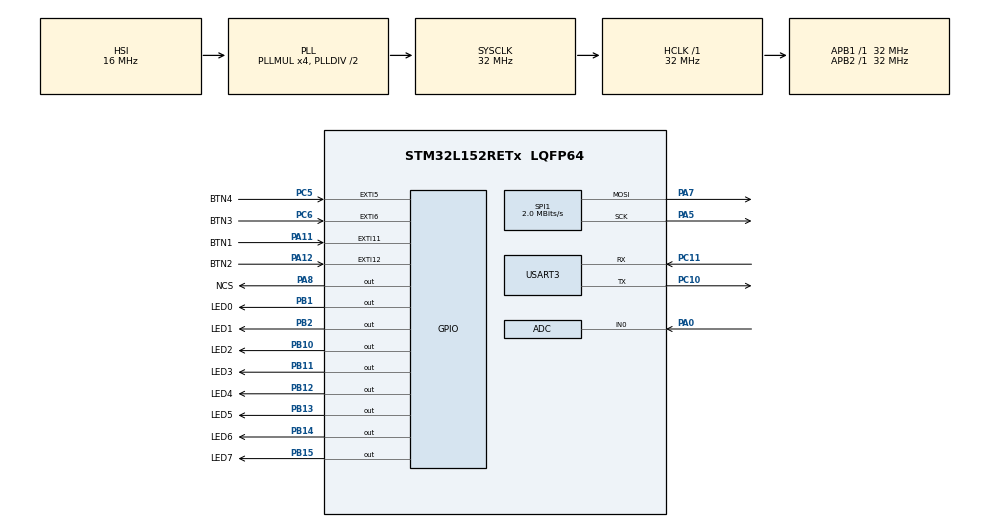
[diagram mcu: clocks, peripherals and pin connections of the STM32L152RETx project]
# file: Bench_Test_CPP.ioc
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ADC.Channel-0\#ChannelRegularConversion=ADC_CHANNEL_0
ADC.ContinuousConvMode=ENABLE
ADC.DMAContinuousRequests=DISABLE
ADC.EnableAnalogWatchDog=true
ADC.HighThreshold=4094
ADC.ITMode=ENABLE
ADC.NbrOfConversionFlag=1
ADC.Rank-0\#ChannelRegularConversion=1
ADC.SamplingTime-0\#ChannelRegularConversion=ADC_SAMPLETIME_4CYCLES
IWDG.Prescaler=IWDG_PRESCALER_4
IWDG.Reload=4095
Mcu.Family=STM32L1
Mcu.Name=STM32L152RETx
Mcu.Package=LQFP64
NVIC.ADC1_IRQn=true\:0\:0\:false\:false\:true\:true\:true\:true
NVIC.EXTI15_10_IRQn=true\:0\:0\:false\:false\:true\:true\:true\:true
NVIC.EXTI9_5_IRQn=true\:0\:0\:false\:false\:true\:true\:true\:true
NVIC.PriorityGroup=NVIC_PRIORITYGROUP_0
NVIC.TIM3_IRQn=true\:0\:0\:false\:false\:true\:true\:true\:true
NVIC.TIM6_IRQn=true\:0\:0\:false\:false\:true\:true\:true\:true
PA0-WKUP1.Mode=IN0
PA0-WKUP1.Signal=ADC_IN0
PA11.GPIO_Label=BTN1
PA11.Signal=GPXTI11
PA12.GPIO_Label=BTN2
PA12.GPIO_PuPd=GPIO_PULLDOWN
PA12.Signal=GPXTI12
PA13.Mode=Serial_Wire
PA13.Signal=SYS_JTMS-SWDIO
PA14.Mode=Serial_Wire
PA14.Signal=SYS_JTCK-SWCLK
PA5.Mode=TX_Only_Simplex_Unidirect_Master
PA5.Signal=SPI1_SCK
PA7.Mode=TX_Only_Simplex_Unidirect_Master
PA7.Signal=SPI1_MOSI
PA8.GPIO_Label=NCS
PA8.Signal=GPIO_Output
PB1.GPIO_Label=LED0
PB1.Signal=GPIO_Output
PB10.GPIO_Label=LED2
PB10.Signal=GPIO_Output
PB11.GPIO_Label=LED3
PB11.Signal=GPIO_Output
PB12.GPIO_Label=LED4
PB12.Signal=GPIO_Output
PB13.GPIO_Label=LED5
PB13.Signal=GPIO_Output
PB14.GPIO_Label=LED6
PB14.Signal=GPIO_Output
PB15.GPIO_Label=LED7
PB15.Signal=GPIO_Output
PB2.GPIO_Label=LED1
PB2.Signal=GPIO_Output
PB4.GPIO_Label=Moteur
PB4.Signal=S_TIM3_CH1
PC10.Mode=Asynchronous
PC10.Signal=USART3_TX
PC11.Mode=Asynchronous
PC11.Signal=USART3_RX
PC5.GPIO_Label=BTN4
PC5.Signal=GPXTI5
PC6.GPIO_Label=BTN3
PC6.Signal=GPXTI6
ProjectManager.HeapSize=0x200
ProjectManager.StackSize=0x400
ProjectManager.TargetToolchain=STM32CubeIDE
RCC.48MHZClocksFreq_Value=32000000
RCC.AHBFreq_Value=32000000
RCC.APB1Freq_Value=32000000
RCC.APB1TimFreq_Value=32000000
RCC.APB2Freq_Value=32000000
RCC.APB2TimFreq_Value=32000000
RCC.HCLKFreq_Value=32000000
RCC.HSE_VALUE=8000000
RCC.HSI_VALUE=16000000
RCC.LSE_VALUE=32768
RCC.MSI_VALUE=2097000
RCC.PLLMUL=RCC_PLL_MUL4
RCC.RTCClockSelectionVirtual=RCC_RTCCLKSOURCE_LSE
RCC.SYSCLKFreq_VALUE=32000000
RCC.SYSCLKSource=RCC_SYSCLKSOURCE_PLLCLK
RCC.USBOutput=48000000
RCC.VCOOutputFreq_Value=64000000
SH.S_TIM3_CH1.0=TIM3_CH1
SPI1.BaudRatePrescaler=SPI_BAUDRATEPRESCALER_16
SPI1.CalculateBaudRate=2.0 MBits/s
SPI1.Direction=SPI_DIRECTION_2LINES
SPI1.Mode=SPI_MODE_MASTER
SPI1.VirtualType=VM_MASTER
TIM3.Channel-PWM\ Generation1\ No\ Output=TIM_CHANNEL_1
TIM3.Channel-PWM\ Generation2\ No\ Output=TIM_CHANNEL_2
TIM3.Period=7
TIM3.Prescaler=32000
TIM6.Prescaler=3200
USART3.VirtualMode=VM_ASYNC
VP_IWDG_VS_IWDG.Mode=IWDG_Activate
VP_TIM3_VS_ClockSourceINT.Mode=Internal
VP_TIM3_VS_no_output1.Mode=PWM Generation1 No Output
VP_TIM3_VS_no_output2.Mode=PWM Generation2 No Output
VP_TIM6_VS_ClockSourceINT.Mode=Enable_Timer
board=NUCLEO-L152RE

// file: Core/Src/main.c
/* USER CODE BEGIN Header */
/**
 ******************************************************************************
 * @file           : main.c
 * @brief          : Main program body
 ******************************************************************************
 * @attention
 *
 * Copyright (c) 2024 STMicroelectronics.
 * All rights reserved.
 *
 * This software is licensed under terms that can be found in the LICENSE file
 * in the root directory of this software component.
 * If no LICENSE file comes with this software, it is provided AS-IS.
 *
 ******************************************************************************
 */
/* USER CODE END Header */
#include "main.h"

/* USER CODE BEGIN Includes */
#include "main.hpp"
#include "max7219.h"
/* USER CODE END Includes */

ADC_HandleTypeDef hadc;

IWDG_HandleTypeDef hiwdg;

SPI_HandleTypeDef hspi1;

TIM_HandleTypeDef htim3;
TIM_HandleTypeDef htim6;

UART_HandleTypeDef huart3;

void SystemClock_Config(void);
static void MX_GPIO_Init(void);
static void MX_ADC_Init(void);
static void MX_SPI1_Init(void);
static void MX_TIM3_Init(void);
static void MX_TIM6_Init(void);
static void MX_IWDG_Init(void);
static void MX_USART3_UART_Init(void);

int main(void) {

	/* MCU Configuration--------------------------------------------------------*/

	/* Reset of all peripherals, Initializes the Flash interface and the Systick. */
	HAL_Init();

	/* Configure the system clock */
	SystemClock_Config();

	/* Initialize all configured peripherals */
	MX_GPIO_Init();
	MX_ADC_Init();
	MX_SPI1_Init();
	MX_TIM3_Init();
	MX_TIM6_Init();
	MX_IWDG_Init();
	MX_USART3_UART_Init();
	/* USER CODE BEGIN 2 */
	HAL_DBGMCU_EnableDBGSleepMode();
	HAL_SuspendTick();
	HAL_PWR_EnterSLEEPMode(PWR_MAINREGULATOR_ON, PWR_SLEEPENTRY_WFI);
	SystemClock_Config(); // recommended
	HAL_ResumeTick();

	main_cpp();

	/* USER CODE END 2 */

	/* Infinite loop */
	while (1) {

		/* USER CODE BEGIN 3 */

//	  max7219_display_no_decode(0, 0xA1);
	}
	/* USER CODE END 3 */
}

void SystemClock_Config(void) {
	RCC_OscInitTypeDef RCC_OscInitStruct = { 0 };
	RCC_ClkInitTypeDef RCC_ClkInitStruct = { 0 };

	/** Configure the main internal regulator output voltage
	 */
	__HAL_PWR_VOLTAGESCALING_CONFIG(PWR_REGULATOR_VOLTAGE_SCALE1);

	/** Initializes the RCC Oscillators according to the specified parameters
	 * in the RCC_OscInitTypeDef structure.
	 */
	RCC_OscInitStruct.OscillatorType = RCC_OSCILLATORTYPE_HSI
			| RCC_OSCILLATORTYPE_LSI;
	RCC_OscInitStruct.HSIState = RCC_HSI_ON;
	RCC_OscInitStruct.HSICalibrationValue = RCC_HSICALIBRATION_DEFAULT;
	RCC_OscInitStruct.LSIState = RCC_LSI_ON;
	RCC_OscInitStruct.PLL.PLLState = RCC_PLL_ON;
	RCC_OscInitStruct.PLL.PLLSource = RCC_PLLSOURCE_HSI;
	RCC_OscInitStruct.PLL.PLLMUL = RCC_PLL_MUL4;
	RCC_OscInitStruct.PLL.PLLDIV = RCC_PLL_DIV2;
	if (HAL_RCC_OscConfig(&RCC_OscInitStruct) != HAL_OK) {
		Error_Handler();
	}

	/** Initializes the CPU, AHB and APB buses clocks
	 */
	RCC_ClkInitStruct.ClockType = RCC_CLOCKTYPE_HCLK | RCC_CLOCKTYPE_SYSCLK
			| RCC_CLOCKTYPE_PCLK1 | RCC_CLOCKTYPE_PCLK2;
	RCC_ClkInitStruct.SYSCLKSource = RCC_SYSCLKSOURCE_PLLCLK;
	RCC_ClkInitStruct.AHBCLKDivider = RCC_SYSCLK_DIV1;
	RCC_ClkInitStruct.APB1CLKDivider = RCC_HCLK_DIV1;
	RCC_ClkInitStruct.APB2CLKDivider = RCC_HCLK_DIV1;

	if (HAL_RCC_ClockConfig(&RCC_ClkInitStruct, FLASH_LATENCY_1) != HAL_OK) {
		Error_Handler();
	}
}

static void MX_ADC_Init(void) {

	ADC_AnalogWDGConfTypeDef AnalogWDGConfig = { 0 };
	ADC_ChannelConfTypeDef sConfig = { 0 };

	/** Configure the global features of the ADC (Clock, Resolution, Data Alignment and number of conversion)
	 */
	hadc.Instance = ADC1;
	hadc.Init.ClockPrescaler = ADC_CLOCK_ASYNC_DIV1;
	hadc.Init.Resolution = ADC_RESOLUTION_12B;
	hadc.Init.DataAlign = ADC_DATAALIGN_RIGHT;
	hadc.Init.ScanConvMode = ADC_SCAN_DISABLE;
	hadc.Init.EOCSelection = ADC_EOC_SEQ_CONV;
	hadc.Init.LowPowerAutoWait = ADC_AUTOWAIT_DISABLE;
	hadc.Init.LowPowerAutoPowerOff = ADC_AUTOPOWEROFF_DISABLE;
	hadc.Init.ChannelsBank = ADC_CHANNELS_BANK_A;
	hadc.Init.ContinuousConvMode = ENABLE;
	hadc.Init.NbrOfConversion = 1;
	hadc.Init.DiscontinuousConvMode = DISABLE;
	hadc.Init.ExternalTrigConv = ADC_SOFTWARE_START;
	hadc.Init.ExternalTrigConvEdge = ADC_EXTERNALTRIGCONVEDGE_NONE;
	hadc.Init.DMAContinuousRequests = DISABLE;
	if (HAL_ADC_Init(&hadc) != HAL_OK) {
		Error_Handler();
	}

	/** Configure the analog watchdog
	 */
	AnalogWDGConfig.WatchdogMode = ADC_ANALOGWATCHDOG_SINGLE_REG;
	AnalogWDGConfig.Channel = ADC_CHANNEL_0;
	AnalogWDGConfig.ITMode = ENABLE;
	AnalogWDGConfig.HighThreshold = 4094;
	AnalogWDGConfig.LowThreshold = 0;
	if (HAL_ADC_AnalogWDGConfig(&hadc, &AnalogWDGConfig) != HAL_OK) {
		Error_Handler();
	}

	/** Configure for the selected ADC regular channel its corresponding rank in the sequencer and its sample time.
	 */
	sConfig.Channel = ADC_CHANNEL_0;
	sConfig.Rank = ADC_REGULAR_RANK_1;
	sConfig.SamplingTime = ADC_SAMPLETIME_4CYCLES;
	if (HAL_ADC_ConfigChannel(&hadc, &sConfig) != HAL_OK) {
		Error_Handler();
	}

}

static void MX_IWDG_Init(void) {

	hiwdg.Instance = IWDG;
	hiwdg.Init.Prescaler = IWDG_PRESCALER_4;
	hiwdg.Init.Reload = 4095;
	if (HAL_IWDG_Init(&hiwdg) != HAL_OK) {
		Error_Handler();
	}

}

static void MX_SPI1_Init(void) {

	/* SPI1 parameter configuration*/
	hspi1.Instance = SPI1;
	hspi1.Init.Mode = SPI_MODE_MASTER;
	hspi1.Init.Direction = SPI_DIRECTION_2LINES;
	hspi1.Init.DataSize = SPI_DATASIZE_8BIT;
	hspi1.Init.CLKPolarity = SPI_POLARITY_LOW;
	hspi1.Init.CLKPhase = SPI_PHASE_1EDGE;
	hspi1.Init.NSS = SPI_NSS_SOFT;
	hspi1.Init.BaudRatePrescaler = SPI_BAUDRATEPRESCALER_16;
	hspi1.Init.FirstBit = SPI_FIRSTBIT_MSB;
	hspi1.Init.TIMode = SPI_TIMODE_DISABLE;
	hspi1.Init.CRCCalculation = SPI_CRCCALCULATION_DISABLE;
	hspi1.Init.CRCPolynomial = 10;
	if (HAL_SPI_Init(&hspi1) != HAL_OK) {
		Error_Handler();
	}

}

static void MX_TIM3_Init(void) {

	TIM_ClockConfigTypeDef sClockSourceConfig = { 0 };
	TIM_MasterConfigTypeDef sMasterConfig = { 0 };
	TIM_OC_InitTypeDef sConfigOC = { 0 };

	htim3.Instance = TIM3;
	htim3.Init.Prescaler = 32000;
	htim3.Init.CounterMode = TIM_COUNTERMODE_UP;
	htim3.Init.Period = 7;
	htim3.Init.ClockDivision = TIM_CLOCKDIVISION_DIV1;
	htim3.Init.AutoReloadPreload = TIM_AUTORELOAD_PRELOAD_DISABLE;
	if (HAL_TIM_Base_Init(&htim3) != HAL_OK) {
		Error_Handler();
	}
	sClockSourceConfig.ClockSource = TIM_CLOCKSOURCE_INTERNAL;
	if (HAL_TIM_ConfigClockSource(&htim3, &sClockSourceConfig) != HAL_OK) {
		Error_Handler();
	}
	if (HAL_TIM_PWM_Init(&htim3) != HAL_OK) {
		Error_Handler();
	}
	sMasterConfig.MasterOutputTrigger = TIM_TRGO_RESET;
	sMasterConfig.MasterSlaveMode = TIM_MASTERSLAVEMODE_DISABLE;
	if (HAL_TIMEx_MasterConfigSynchronization(&htim3, &sMasterConfig)
			!= HAL_OK) {
		Error_Handler();
	}
	sConfigOC.OCMode = TIM_OCMODE_PWM1;
	sConfigOC.Pulse = 0;
	sConfigOC.OCPolarity = TIM_OCPOLARITY_HIGH;
	sConfigOC.OCFastMode = TIM_OCFAST_DISABLE;
	if (HAL_TIM_PWM_ConfigChannel(&htim3, &sConfigOC, TIM_CHANNEL_1)
			!= HAL_OK) {
		Error_Handler();
	}
	if (HAL_TIM_PWM_ConfigChannel(&htim3, &sConfigOC, TIM_CHANNEL_2)
			!= HAL_OK) {
		Error_Handler();
	}

}

static void MX_TIM6_Init(void) {

	TIM_MasterConfigTypeDef sMasterConfig = { 0 };

	htim6.Instance = TIM6;
	htim6.Init.Prescaler = 3200;
	htim6.Init.CounterMode = TIM_COUNTERMODE_UP;
	htim6.Init.Period = 65535;
	htim6.Init.AutoReloadPreload = TIM_AUTORELOAD_PRELOAD_DISABLE;
	if (HAL_TIM_Base_Init(&htim6) != HAL_OK) {
		Error_Handler();
	}
	sMasterConfig.MasterOutputTrigger = TIM_TRGO_RESET;
	sMasterConfig.MasterSlaveMode = TIM_MASTERSLAVEMODE_DISABLE;
	if (HAL_TIMEx_MasterConfigSynchronization(&htim6, &sMasterConfig)
			!= HAL_OK) {
		Error_Handler();
	}

}

static void MX_USART3_UART_Init(void) {

	huart3.Instance = USART3;
	huart3.Init.BaudRate = 115200;
	huart3.Init.WordLength = UART_WORDLENGTH_8B;
	huart3.Init.StopBits = UART_STOPBITS_1;
	huart3.Init.Parity = UART_PARITY_NONE;
	huart3.Init.Mode = UART_MODE_TX_RX;
	huart3.Init.HwFlowCtl = UART_HWCONTROL_NONE;
	huart3.Init.OverSampling = UART_OVERSAMPLING_16;
	if (HAL_UART_Init(&huart3) != HAL_OK) {
		Error_Handler();
	}

}

static void MX_GPIO_Init(void) {
	GPIO_InitTypeDef GPIO_InitStruct = { 0 };

	/* GPIO Ports Clock Enable */
	__HAL_RCC_GPIOA_CLK_ENABLE();
	__HAL_RCC_GPIOC_CLK_ENABLE();
	__HAL_RCC_GPIOB_CLK_ENABLE();

	/*Configure GPIO pin Output Level */
	HAL_GPIO_WritePin(GPIOB,
			LED0_Pin | LED1_Pin | LED2_Pin | LED3_Pin | LED4_Pin | LED5_Pin
					| LED6_Pin | LED7_Pin, GPIO_PIN_RESET);

	/*Configure GPIO pin Output Level */
	HAL_GPIO_WritePin(NCS_GPIO_Port, NCS_Pin, GPIO_PIN_RESET);

	/*Configure GPIO pins : BTN4_Pin BTN3_Pin */
	GPIO_InitStruct.Pin = BTN4_Pin | BTN3_Pin;
	GPIO_InitStruct.Mode = GPIO_MODE_IT_RISING;
	GPIO_InitStruct.Pull = GPIO_NOPULL;
	HAL_GPIO_Init(GPIOC, &GPIO_InitStruct);

	/*Configure GPIO pins : LED0_Pin LED1_Pin LED2_Pin LED3_Pin
	 LED4_Pin LED5_Pin LED6_Pin LED7_Pin */
	GPIO_InitStruct.Pin = LED0_Pin | LED1_Pin | LED2_Pin | LED3_Pin | LED4_Pin
			| LED5_Pin | LED6_Pin | LED7_Pin;
	GPIO_InitStruct.Mode = GPIO_MODE_OUTPUT_PP;
	GPIO_InitStruct.Pull = GPIO_NOPULL;
	GPIO_InitStruct.Speed = GPIO_SPEED_FREQ_LOW;
	HAL_GPIO_Init(GPIOB, &GPIO_InitStruct);

	/*Configure GPIO pin : NCS_Pin */
	GPIO_InitStruct.Pin = NCS_Pin;
	GPIO_InitStruct.Mode = GPIO_MODE_OUTPUT_PP;
	GPIO_InitStruct.Pull = GPIO_NOPULL;
	GPIO_InitStruct.Speed = GPIO_SPEED_FREQ_LOW;
	HAL_GPIO_Init(NCS_GPIO_Port, &GPIO_InitStruct);

	/*Configure GPIO pin : BTN1_Pin */
	GPIO_InitStruct.Pin = BTN1_Pin;
	GPIO_InitStruct.Mode = GPIO_MODE_IT_RISING;
	GPIO_InitStruct.Pull = GPIO_NOPULL;
	HAL_GPIO_Init(BTN1_GPIO_Port, &GPIO_InitStruct);

	/*Configure GPIO pin : BTN2_Pin */
	GPIO_InitStruct.Pin = BTN2_Pin;
	GPIO_InitStruct.Mode = GPIO_MODE_IT_RISING;
	GPIO_InitStruct.Pull = GPIO_PULLDOWN;
	HAL_GPIO_Init(BTN2_GPIO_Port, &GPIO_InitStruct);

	/* EXTI interrupt init*/
	HAL_NVIC_SetPriority(EXTI9_5_IRQn, 0, 0);
	HAL_NVIC_EnableIRQ(EXTI9_5_IRQn);

	HAL_NVIC_SetPriority(EXTI15_10_IRQn, 0, 0);
	HAL_NVIC_EnableIRQ(EXTI15_10_IRQn);

}

void Error_Handler(void) {
	__disable_irq();
	while (1) {
	}
}
